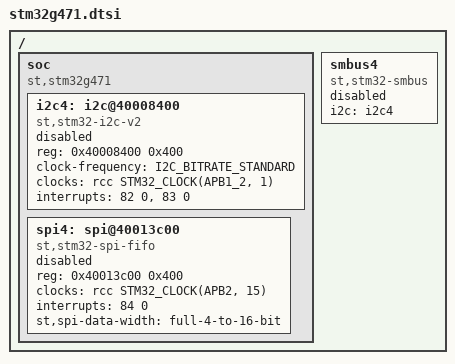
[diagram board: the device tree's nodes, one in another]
/*
 * Copyright (c) 2026 STMicroelectronics
 *
 * SPDX-License-Identifier: Apache-2.0
 */

#include <st/g4/stm32g491.dtsi>

/ {
	soc {
		compatible = "st,stm32g471", "st,stm32g4", "simple-bus";

		i2c4: i2c@40008400 {
			compatible = "st,stm32-i2c-v2";
			reg = <0x40008400 0x400>;
			clock-frequency = <I2C_BITRATE_STANDARD>;
			#address-cells = <1>;
			#size-cells = <0>;
			clocks = <&rcc STM32_CLOCK(APB1_2, 1)>;
			interrupts = <82 0>, <83 0>;
			interrupt-names = "event", "error";
			status = "disabled";
		};

		spi4: spi@40013c00 {
			compatible = "st,stm32-spi-fifo", "st,stm32-spi";
			reg = <0x40013c00 0x400>;
			#address-cells = <1>;
			#size-cells = <0>;
			clocks = <&rcc STM32_CLOCK(APB2, 15)>;
			interrupts = <84 0>;
			st,spi-data-width = "full-4-to-16-bit";
			status = "disabled";
		};
	};

	smbus4: smbus4 {
		compatible = "st,stm32-smbus";
		#address-cells = <1>;
		#size-cells = <0>;
		i2c = <&i2c4>;
		status = "disabled";
	};
};
